# RK3399-AP register map
File version: 1
CPU: CA7 r0p1, little endian, MPU, FPU, I-cache, D-cache, VTOR, 4 interrupt priority bits, 0 interrupts
Registers are 32-bit, read-write, reset 0x0 unless marked. A register's access mark holds for its fields unless they carry their own. Offsets are from the block's base; [hi:lo] are bit positions.

## SPDIF
Base 0xFF870000
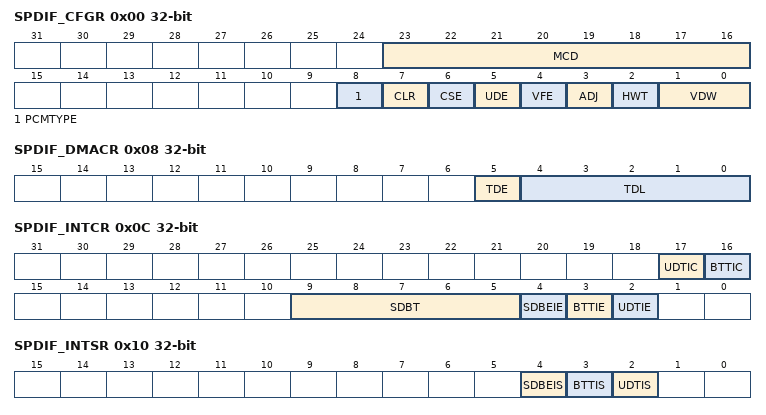
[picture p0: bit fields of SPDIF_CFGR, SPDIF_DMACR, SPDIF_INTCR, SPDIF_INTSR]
0x00 SPDIF_CFGR access per field — Transfer Configuration Register
  [23:16] MCD rw — mclk divider Fmclk/Fsdo This parameter can be calculated by Fmclk/(Fs*128). Fs=the sample frequency be wanted
  [8] PCMTYPE rw — PCM type 0: linear PCM 1: non-linear PCM
  [7] CLR wo — mclk domain logic clear Write 1 to clear mclk domain logic. Read return zero.
  [6] CSE rw — Channel status enable 0: disable 1: enable The bit should be set to 1 when the channel conveys non-linear PCM
  [5] UDE rw — User data enable 0: disable 1: enable
  [4] VFE rw — Validity flag enable 0: disable 1: enable
  [3] ADJ rw — audio data justified 0: Right justified 1: Left justified
  [2] HWT rw — Halfword word transform enable 0: disable 1: enable It is valid only when the valid data width is 16bit.
  [1:0] VDW rw — Valid data width 00: 16bit 01: 20bit 10: 24bit 11: reserved The valid data width is 16bit only for non-linear PCM
0x04 SPDIF_SDBLR — Sample Date Buffer Level Register
  [5:0] SDBLR — Sample Date Buffer Level Register Contains the number of valid data entries in the sample data buffer.
0x08 SPDIF_DMACR — DMA Control Register
  [5] TDE — Transmit DMA Enable 0: Transmit DMA disabled 1: Transmit DMA enabled
  [4:0] TDL — Transmit Data Level This bit field controls the level at which a DMA request is made by the transmit logic. It is equal to the watermark level; that is, the dma_tx_req signal is generated when the number of valid data entries in the Sample Date Buffer is equal to or below this field value
0x0C SPDIF_INTCR — Interrupt Control Register
  [17] UDTIC write-1-clears — User Data Interrupt Clear Write \'1\' to clear the user data interrupt.
  [16] BTTIC write-1-clears — Block/Data burst transfer finish interrupt clear Write 1 to clear the interrupt.
  [9:5] SDBT — Sample Date Buffer Threshold Sample Date Buffer Threshold for empty interrupt
  [4] SDBEIE — Sample Date Buffer empty interrupt enable 0: disable 1: enable
  [3] BTTIE — Block transfer/repetition period end interrupt enable When enabled, an interrupt will be asserted when the block transfer is finished if the channel conveys linear PCM or when the repetition period is reached if the channel conveys non-linear PCM. 0: disable 1: enable
  [2] UDTIE — User Data Interrupt 0: disable 1: enable If enabled, an interrupt will be asserted when the content of the user data register is fed into the corresponding shadow register
0x10 SPDIF_INTSR — Interrupt Status Register
  [4] SDBEIS — Sample Date Buffer empty interrupt status 0: inactive 1: active
  [3] BTTIS — Block/Data burst transfer interrupt status 0: inactive 1: active
  [2] UDTIS — User Data Interrupt Status 0: inactive 1: active
0x18 SPDIF_XFER — Transfer Start Register
  [0] XFER — Transfer Start Register Transfer Start Register
0x20 SPDIF_SMPDR — Sample Data Register
  [31:0] SMPDR — Sample Data Register Sample Data Register VLDFR_SUB_1 Validity Flag Subframe 1 Validity Flag Register 0 VLDFR_SUB_0 Validity Flag Subframe 0 Validity Flag for Subframe 0 USR_SUB_1 User Data Subframe 1 User Data Bit for Subframe 1 USR_SUB_0 User Data Subframe 0 User Data Bit for Subframe 0 CHNSR_SUB_1 Channel Status Subframe 1 Channel Status Bit for Subframe 1 CHNSR_SUB_0 Channel Status Subframe 0 Channel Status Bit for Subframe 0
0x60 SPDIF_VLDFRn access not given — Validity Flag Register n
0x90 SPDIF_USRDRn access not given — User Data Register n
0xC0 SPDIF_CHNSRn access not given — Channel Status Register n
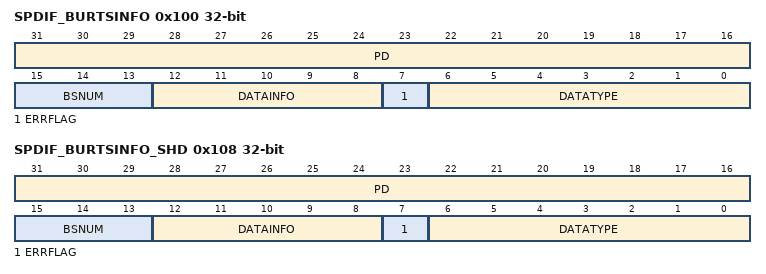
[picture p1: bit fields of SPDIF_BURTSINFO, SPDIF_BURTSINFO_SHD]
0x100 SPDIF_BURTSINFO — Channel Burst Info Register
  [31:16] PD — pd Preamble Pd for non-linear pcm, indicating the length of burst payload in unit of bytes or bits.
  [15:13] BSNUM — Bitstream Number This field indicates the bitstream number. Usually the bitstream number is 0.
  [12:8] DATAINFO — Data-type-dependent info This field gives the data-type-dependent info
  [7] ERRFLAG — Error Flag 0: indicates a valid burst-payload 1: indicates that the burst-payload may contain errors
  [6:0] DATATYPE — Data type 0000000: null data 0000001: AC-3 data 0000011: Pause data 0000100: MPEG-1 layer 1 data 0000101: MPEG-1 layer 2 or 3 data or MPEG-2 without extension 0000110: MPEG-2 data with extension 0000111: MPEG-2 AAC 0001000: MPEG-2, layer-1 low sampling frequency 0001001: MPEG-2, layer-2 low sampling frequency 0001010: MPEG-2, layer-3 low sampling frequency 0001011: DTS type I 0001100: DTS type II 0001101: DTS type III 0001110: ATRAC 0001111: ATRAC 2/3 0010000: ATRAC-X 0010001: DTS type IV 0010010: WMA professional type I 0110010: WMA professional type II 1010010: WMA professional type III 1110010: WMA professional type IV 0010011: MPEG-2 AAC low sampling frequency 0110011: MPEG-2 AAC low sampling frequency 1010011: MPEG-2 AAC low sampling frequency 1110011: MPEG-2 AAC low sampling frequency 0010100: MPEG-4 AAC 0110100: MPEG-4 AAC 1010100: MPEG-4 AAC 1110100: MPEG-4 AAC 0010101: Enhanced AC-3 0010110: MAT others: reserved
0x104 SPDIF_REPETTION — Channel Repetition Register
  [15:0] REPETTION — Repetition This define the repetition period when the channel conveys non- linear PCM
0x108 SPDIF_BURTSINFO_SHD ro — Shadow Channel Burst Info Register
  [31:16] PD — pd Preamble Pd for non-linear pcm, indicating the length of burst payload in unit of bytes or bits.
  [15:13] BSNUM — Bitstream Number This field indicates the bitstream number. Usually the birstream number is 0.
  [12:8] DATAINFO — Data-type-dependent info This field gives the data-type-dependent info
  [7] ERRFLAG — Error Flag 0: indicates a valid burst-payload 1: indicates that the burst-payload may contain errors
  [6:0] DATATYPE — Data type 0000000: null data 0000001: AC-3 data 0000011: Pause data 0000100: MPEG-1 layer 1 data 0000101: MPEG-1 layer 2 or 3 data or MPEG-2 without extension 0000110: MPEG-2 data with extension 0000111: MPEG-2 AAC 0001000: MPEG-2, layer-1 low sampling frequency 0001001: MPEG-2, layer-2 low sampling frequency 0001010: MPEG-2, layer-3 low sampling frequency 0001011: DTS type I 0001100: DTS type II 0001101: DTS type III 0001110: ATRAC 0001111: ATRAC 2/3 0010000: ATRAC-X 0010001: DTS type IV 0010010: WMA professional type I 0110010: WMA professional type II 1010010: WMA professional type III 1110010: WMA professional type IV 0010011: MPEG-2 AAC low sampling frequency 0110011: MPEG-2 AAC low sampling frequency 1010011: MPEG-2 AAC low sampling frequency 1110011: MPEG-2 AAC low sampling frequency 0010100: MPEG-4 AAC 0110100: MPEG-4 AAC 1010100: MPEG-4 AAC 1110100: MPEG-4 AAC 0010101: Enhanced AC-3 0010110: MAT others: reserved
0x10C SPDIF_REPETTION_SHD ro — Shadow Channel Repetition Register
  [15:0] REPETTION — Repetition This register provides the repetition of the bitstream when channel conveys non-linear PCM. In the design, it defines the length between Pa of the two consecutive data-burst. For the same audio format, the definition is different. Please convert the actual repetition in order to comply with the design. USR_SUB_1 User Data Subframe 1 User Data Bit for Subframe 1 USR_SUB_0 User Data Subframe 0 User Data Bit for Subframe 0 Table 14-2 Interface Between SPDIF and HDMI
0x190 SPDIF_USRDR_SHDn access not given — Shadow User Data Register n
